# MPU_1 register map
Vendor: Texas Instruments
Peripheral module from a debugger description file (folder msp430).
Registers are 16-bit, read-write, reset 0x0 unless marked. A register's access mark holds for its fields unless they carry their own. Offsets are as the file gives them; lines under a group give offsets from that group; [hi:lo] are bit positions; {n}, {i} and the like mark numbered series; 'fields as' and 'values as' point back to an identical list; <NAME> marks a mode.

## MPU
0x5A0 MPUCTL0 — MPU Control Register 0
  [0] MPUENA — MPU Enable
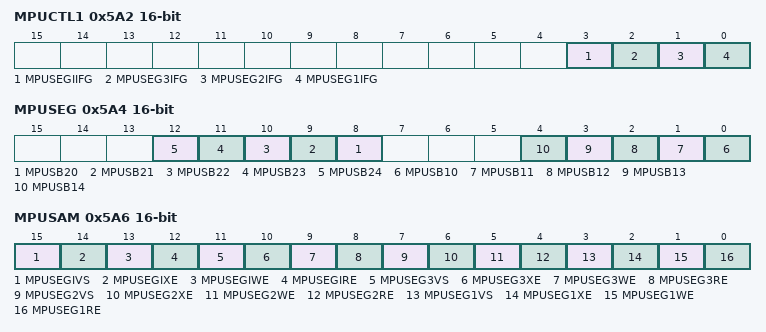
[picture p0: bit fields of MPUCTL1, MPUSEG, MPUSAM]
0x5A2 MPUCTL1 — MPU Control Register 1
  [3] MPUSEGIIFG — MPU Info Memory Segment violation interupt flag
  [2] MPUSEG3IFG — MPU Main Memory Segment 3 violation interupt flag
  [1] MPUSEG2IFG — MPU Main Memory Segment 2 violation interupt flag
  [0] MPUSEG1IFG — MPU Main Memory Segment 1 violation interupt flag
0x5A4 MPUSEG — MPU Segmentation Register
  [n-12] MPUSB{n} (n=20..24) — MPU Segment Border 2 Bit: {n-20}
  [n-10] MPUSB{n} (n=10..14) — MPU Segment Border 1 Bit: {n-10}
0x5A6 MPUSAM — MPU Access Management Register
  [15] MPUSEGIVS — MPU Info memory Segment Violation select
  [14] MPUSEGIXE — MPU Info memory Segment Execute enable
  [13] MPUSEGIWE — MPU Info memory Segment Write enable
  [12] MPUSEGIRE — MPU Info memory Segment Read enable
  [11] MPUSEG3VS — MPU Main memory Segment 3 Violation select
  [10] MPUSEG3XE — MPU Main memory Segment 3 Execute enable
  [9] MPUSEG3WE — MPU Main memory Segment 3 Write enable
  [8] MPUSEG3RE — MPU Main memory Segment 3 Read enable
  [7] MPUSEG2VS — MPU Main memory Segment 2 Violation select
  [6] MPUSEG2XE — MPU Main memory Segment 2 Execute enable
  [5] MPUSEG2WE — MPU Main memory Segment 2 Write enable
  [4] MPUSEG2RE — MPU Main memory Segment 2 Read enable
  [3] MPUSEG1VS — MPU Main memory Segment 1 Violation select
  [2] MPUSEG1XE — MPU Main memory Segment 1 Execute enable
  [1] MPUSEG1WE — MPU Main memory Segment 1 Write enable
  [0] MPUSEG1RE — MPU Main memory Segment 1 Read enable
